# S6E2CC register map
File version: 1.1
CPU: 
Registers are 8-bit, read-write, reset 0x0 unless marked. A register's access mark holds for its fields unless they carry their own. Offsets are from the block's base; [hi:lo] are bit positions; {n}, {i} and the like mark numbered series.

## ETHERNET_MAC0
Base 0x40064000
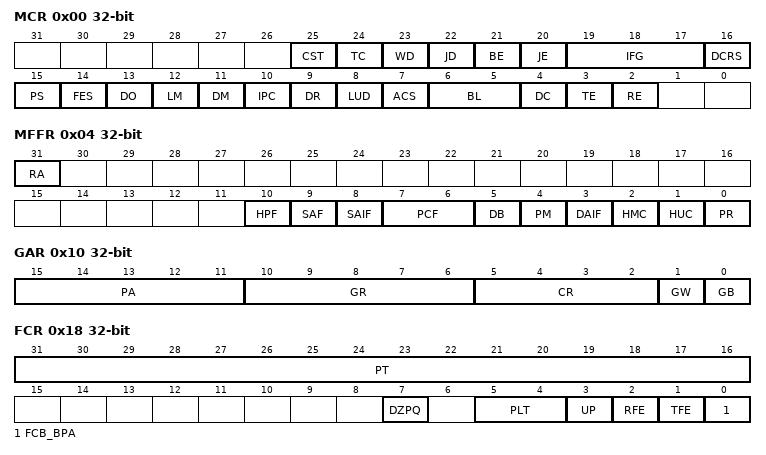
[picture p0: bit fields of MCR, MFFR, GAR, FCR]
0x00 MCR 32-bit — MAC Configuration Register
  [25] CST — CRC stripping for Type frames
  [24] TC — Transmit Configuration in RGMII
  [23] WD — Watchdog Disable
  [22] JD — Jabber Disable
  [21] BE — Frame Burst Enable
  [20] JE — Jumbo Frame Enable
  [19:17] IFG — Inter-Frame GAP
  [16] DCRS — Disable Carrier Sense During Transaction
  [15] PS — Port Select
  [14] FES — Speed
  [13] DO — Disable Receive Own
  [12] LM — Loop-back Mode
  [11] DM — Duplex mode
  [10] IPC — Checksum Offload
  [9] DR — Disable Retry
  [8] LUD — Link Up/Down in RGMII
  [7] ACS — Automatic Pad/CRC Stripping
  [6:5] BL — Back-off Limit
  [4] DC — Deferral Check
  [3] TE — Transmitter Enable
  [2] RE — Receiver Enable
0x04 MFFR 32-bit — MAC Frame Filter Register
  [31] RA — Receive All
  [10] HPF — Hash or Perfect Filter
  [9] SAF — Source Address Filter
  [8] SAIF — Source Address Inverse Filter
  [7:6] PCF — Pass Control Frames
  [5] DB — Disable Broadcast Frames
  [4] PM — Pass All Multicast
  [3] DAIF — DA Inverse Filtering
  [2] HMC — Hash Multicast
  [1] HUC — Hash Unicast
  [0] PR — Promiscuous Mode
0x08 MHTRH 32-bit — MAC Hash Table Register (High)
  [31:0] HTH — the upper 32 bits of the hash table in the HTH
0x0C MHTRL 32-bit — MAC Hash Table Register (Low)
  [31:0] HTL — the lower 32 bits of the hash table in the HTL
0x10 GAR 32-bit — GMII/MII Address Register
  [15:11] PA — Physical Layer Address
  [10:6] GR — GMII Register
  [5:2] CR — Application Clock Range
  [1] GW — GMII/MII Write
  [0] GB — GMII/MII Busy
0x14 GDR 32-bit — GMII/MII Data Register
  [15:0] GD
0x18 FCR 32-bit — Flow Control Register
  [31:16] PT — Pause Time
  [7] DZPQ — Disable Zero-Quanta Pause
  [5:4] PLT — Pause Low Threshold
  [3] UP — Unicast Pause Frame detect
  [2] RFE — Receive Flow Control Enable
  [1] TFE — Transmit Flow Control Enable
  [0] FCB_BPA — Flow Control Busy/Backpressure Activate
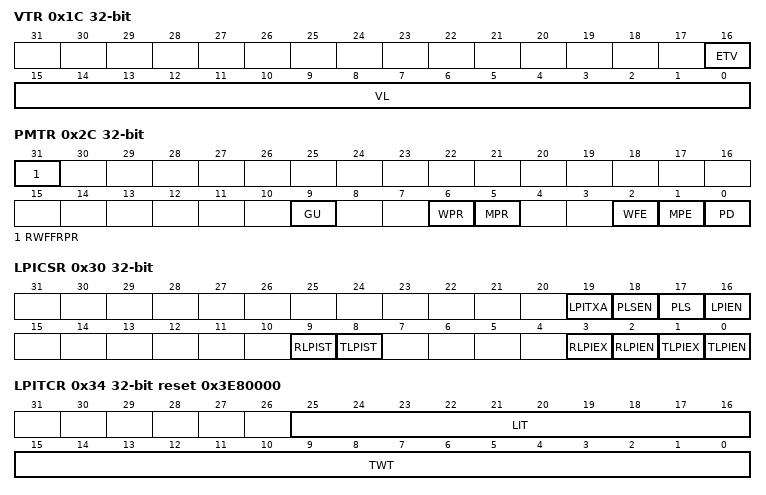
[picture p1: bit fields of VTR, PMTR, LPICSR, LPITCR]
0x1C VTR 32-bit — VLAN TAG Register
  [16] ETV — Enable 12-Bit VLAN Tag Comparison
  [15:0] VL — VLAN Tag Identifier
0x28 RWFFR 32-bit — Remote Wake-up Frame Filter Register
0x2C PMTR 32-bit — PMT Register
  [31] RWFFRPR — Remote Wake-up Frame Filter Register Pointer Reset
  [9] GU — Global Unicast
  [6] WPR — Wake Up Frame Receive
  [5] MPR — Magic Packet Received
  [2] WFE — Wake-Up Frame Enable
  [1] MPE — Magic Packet Enable
  [0] PD — Power Down
0x30 LPICSR 32-bit — LPI Control and Status Register
  [19] LPITXA — LPI TX Automate
  [18] PLSEN — PHY Link Status Enable
  [17] PLS — PHY Link Status
  [16] LPIEN — LPI Enable
  [9] RLPIST ro — Receive LPI State
  [8] TLPIST ro — Transmit LPI State
  [3] RLPIEX ro — Receive LPI Exit
  [2] RLPIEN ro — Receive LPI Entry
  [1] TLPIEX ro — Transmit LPI Exit
  [0] TLPIEN ro — Transmit LPI Entry
0x34 LPITCR 32-bit reset 0x3E80000 — LPI Timers Control Register
  [25:16] LIT — LPI LS TIMER
  [15:0] TWT — LPI TW TIMER
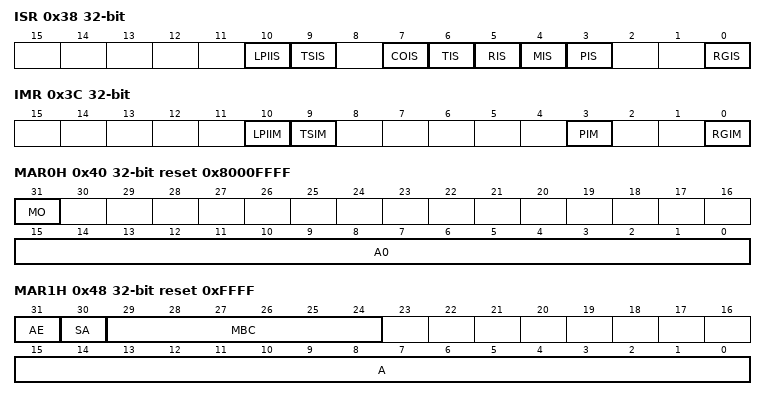
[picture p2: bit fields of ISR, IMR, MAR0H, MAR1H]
0x38 ISR 32-bit ro — Interrupt Status Register
  [10] LPIIS — LPI Interrupt Status
  [9] TSIS — Time Stamp Interrupt Status
  [7] COIS — MMC Receive Checksum Offload Interrupt Status
  [6] TIS — MMC Transmit Interrupt Status
  [5] RIS — MMC Receive Interrupt Status
  [4] MIS — MMC Interrupt Status
  [3] PIS — PMT Interrupt Status
  [0] RGIS — RGMII Interrupt Status
0x3C IMR 32-bit — Interrupt Mask Register
  [10] LPIIM — LPI Interrupt Mask
  [9] TSIM — Time Stamp Interrupt Mask
  [3] PIM — PMT Interrupt Mask
  [0] RGIM — RGMII Interrupt Mask
0x40 MAR0H 32-bit reset 0x8000FFFF — MAC Address0 Register (High)
  [31] MO ro — Must be one
  [15:0] A0 — MAC Address0
0x44 MAR0L 32-bit reset 0xFFFFFFFF — MAC Address0 Register (Low)
  [31:0] A0 — MAC Address0
0x48 MAR1H 32-bit reset 0xFFFF — MAC Address1 Register -High
  [31] AE — Address Enable
  [30] SA — Source Address
  [29:24] MBC — Mask Byte Control
  [15:0] A — MAC Address
0x4C MAR1L 32-bit reset 0xFFFFFFFF — MAC Address1 Register -Low
  [31:0] A — MAC Address
{0x40+8i} MAR{i}H 32-bit reset not defined (i=2..15) — MAC Address{i} Register -High
{0x44+8i} MAR{i}L 32-bit reset not defined (i=2..15) — MAC Address{i} Register -Low
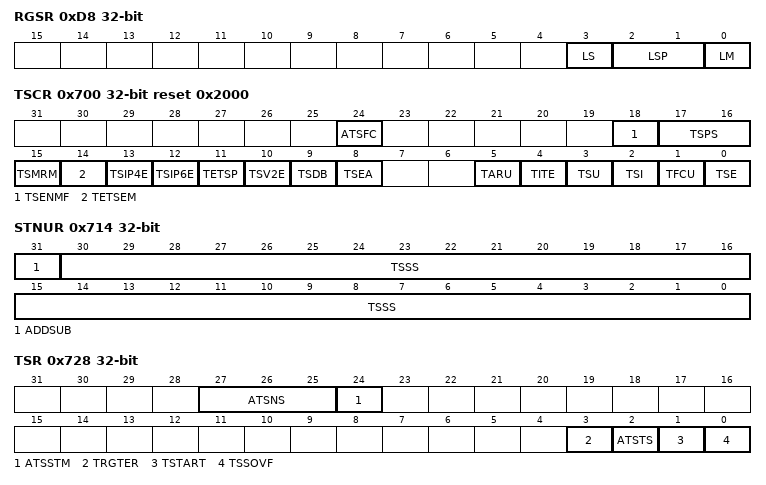
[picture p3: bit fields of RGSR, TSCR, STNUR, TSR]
0xD8 RGSR 32-bit ro — RGMII Status Register)
  [3] LS — Link Status
  [2:1] LSP — Link Speed
  [0] LM — Link Mode
0x100 mmc_cntl 32-bit (reset mask 0x3F) — MMC Control Register
0x104 mmc_intr_rx 32-bit ro (reset mask 0xFFFFFF) — Receive Interrupt Register
0x108 mmc_intr_tx 32-bit ro (reset mask 0x1FFFFFF) — MMC Transmit Interrupt Register
0x10C mmc_intr_mask_rx 32-bit (reset mask 0xFFFFFF) — MMC Receive Interrupt Mask Register
0x110 mmc_intr_mask_tx 32-bit (reset mask 0x1FFFFFF) — MMC Transmit Interrupt Mask Register
0x114 txoctetcount_gb 32-bit ro — "Number of bytes transmitted, exclusive of preamble and retried bytes, in good and bad frames"
0x118 txframecount_gb 32-bit ro — "Number of good and bad frames transmitted, exclusive of retried frames"
0x11C txbroadcastframes_g 32-bit ro — Number of good broadcast frames transmitted
0x120 txmulticastframes_g 32-bit ro — Number of good multicast frames transmitted
0x124 tx64octets_gb 32-bit ro — "Number of good and bad frames transmitted with length of 64 bytes, exclusive of preamble and retried frames"
0x128 tx65to127octets_gb 32-bit ro — "Number of good and bad frames transmitted with length between 65 and 127 (inclusive) bytes, exclusive of preamble and retried frames"
0x12C tx128to255octets_gb 32-bit ro — "Number of good and bad frames transmitted with length between 128 and 255 (inclusive) bytes, exclusive of preamble and retried frames"
0x130 tx256to511octets_gb 32-bit ro — "Number of good and bad frames transmitted with length between 256 and 511 (inclusive) bytes, exclusive of preamble and retried frames"
0x134 tx512to1023octets_gb 32-bit ro — "Number of good and bad frames transmitted with length between 512 and 1023 (inclusive) bytes, exclusive of preamble and retried frames"
0x138 tx1024tomaxoctets_gb 32-bit ro — "Number of good and bad frames transmitted with length between 1024 and Maxsize (inclusive) bytes, exclusive of preamble and retried frames"
0x13C txunicastframes_gb 32-bit ro — Number of good and bad unicast frames transmitted
0x140 txmulticastframes_gb 32-bit ro — Number of good and bad multicast frames transmitted
0x144 txbroadcastframes_gb 32-bit ro — Number of good and bad broadcast frames transmitted
0x148 txunderflowerror 32-bit ro — Number of frames aborted due to frame underflow error
0x14C txsinglecol_g 32-bit ro — Number of successfully transmitted frames after a single collision in Half-duplex mode
0x150 txmulticol_g 32-bit ro — Number of successfully transmitted frames after more than a single collision in Half-duplex mode
0x154 txdeferred 32-bit ro — Number of successfully transmitted frames after a deferral in Half-duplex mode.
0x158 txlatecol 32-bit ro — Number of frames aborted due to late collision error.
0x15C txexesscol 32-bit ro — Number of frames aborted due to excessive (16) collision errors.
0x160 txcarriererror 32-bit ro — Number of frames aborted due to carrier sense error (no carrier or loss of carrier).
0x164 txoctetcount_g 32-bit ro — "Number of bytes transmitted, exclusive of preamble, in good frames only. "
0x168 txframecount_g 32-bit ro — Number of good frames transmitted.
0x16C txexecessdef_g 32-bit ro — Number of frames aborted due to excessive deferral error (deferred for more than two max-sized frame times).
0x170 txpauseframes 32-bit ro — Number of good PAUSE frames transmitted.
0x174 txvlanframes_g 32-bit ro — "Number of good VLAN frames transmitted, exclusive of retried frames. "
0x180 rxframecount_gb 32-bit ro — Number of good and bad frames received.
0x184 rxoctetcount_gb 32-bit ro — "Number of bytes received, exclusive of preamble, in good and bad frames. "
0x188 rxoctetcount_g 32-bit ro — "Number of bytes received, exclusive of preamble, only in good frames. "
0x18C rxbroadcastframes_g 32-bit ro — Number of good broadcast frames received.
0x190 rxmulticastframes_g 32-bit ro — Number of good multicast frames received.
0x194 rxcrcerror 32-bit ro — Number of frames received with CRC error.
0x198 rxallignmenterror 32-bit ro — Number of frames received with alignment (dribble) error. Valid only in 10/100 mode.
0x19C rxrunterror 32-bit ro — Number of frames received with runt (64 bytes and CRC error) error.
0x1A0 rxjabbererror 32-bit ro — Number of frames received with length greater than 1518 bytes with CRC error.
0x1A4 rxundersize_g 32-bit ro — "Number of frames received with length less than 64 bytes, without any errors. "
0x1A8 rxoversize_g 32-bit ro — Number of frames received with length greater than the maxsize without error.
0x1AC rx64octets_gb 32-bit ro — "Number of good and bad frames received with length 64 bytes, exclusive of preamble. "
0x1B0 rx65to127octets_gb 32-bit ro — "Number of good and bad frames received with length between 65 and 127 (inclusive) bytes, exclusive of preamble. "
0x1B4 rx128to255octets_gb 32-bit ro — "Number of good and bad frames received with length between 128 and 255 (inclusive) bytes, exclusive of preamble. "
0x1B8 rx256to511octets_gb 32-bit ro — "Number of good and bad frames received with length between 256 and 511 (inclusive) bytes, exclusive of preamble. "
0x1BC rx512to1023octets_gb 32-bit ro — "Number of good and bad frames received with length between 512 and 1023 (inclusive) bytes, exclusive of preamble. "
0x1C0 rx1024tomaxoctets_gb 32-bit ro — "Number of good and bad frames received with length between 1024 and maxsize (inclusive) bytes, exclusive of preamble. "
0x1C4 rxunicastframes_g 32-bit ro — Number of good unicast frames received.
0x1C8 rxlengtherror 32-bit ro — "Number of frames received with length error (Length type field is not the frame size), for all frames with valid length field. "
0x1CC rxoutofrangetype 32-bit ro — Number of frames received with length/type field not equal to the valid frame size (>1500)
0x1D0 rxpauseframes 32-bit ro — Number of good and valid PAUSE frames received.
0x1D4 rxfifooverflow 32-bit ro — Number of missed received frames due to FIFO overflow.
0x1D8 rxvlanframes_gb 32-bit ro — Number of good and bad VLAN frames received.
0x1DC rxwatchdogerror 32-bit ro — Number of frames received with error due to watchdog timeout error (frames with a data load larger than 2048 bytes).
0x200 mmc_ipc_intr_mask_rx 32-bit (reset mask 0x3FFF3FFF) — MMC Receive Checksum Offload Interrupt Mask Register
0x208 mmc_ipc_intr_rx 32-bit ro (reset mask 0x3FFF3FFF) — MMC Receive Checksum Offload Interrupt Register
0x210 rxipv4_gd_frms 32-bit ro — "Number of good IPv4 datagrams received with the TCP, UDP, or ICMP payload "
0x214 rxipv4_hdrerr_frms 32-bit ro — "Number of IPv4 datagrams received with header errors (checksum, length, or version mismatch) "
0x218 rxipv4_nopay_frms 32-bit ro — "Number of IPv4 datagram frames received that did not have a TCP, UDP, or ICMP payload processed by the Checksum engine "
0x21C rxipv4_frag_frms 32-bit ro — Number of good IPv4 datagrams with fragmentation
0x220 rxipv4_udsbl_frms 32-bit ro — Number of good IPv4 datagrams received that had a UDP payload with checksum disabled
0x224 rxipv6_gd_frms 32-bit ro — "Number of good IPv6 datagrams received with TCP, UDP, or ICMP payloads "
0x228 rxipv6_hdrerr_frms 32-bit ro — Number of IPv6 datagrams received with header errors (length or version mismatch)
0x22C rxipv6_nopay_frms 32-bit ro — "Number of IPv6 datagram frames received that did not have a TCP, UDP, or ICMP payload. This includes all IPv6 datagrams with fragmentation or security extension headers "
0x230 rxudp_gd_frms 32-bit ro — Number of good IP datagrams with a good UDP payload. This counter is not updated when the rxipv4_udsbl_frms counter is incremented.
0x234 rxudp_err_frms 32-bit ro — Number of good IP datagrams whose UDP payload has a checksum error
0x238 rxtcp_gd_frms 32-bit ro — Number of good IP datagrams with a good TCP payload
0x23C rxtcp_err_frms 32-bit ro — Number of good IP datagrams whose TCP payload has a checksum error
0x240 rxicmp_gd_frms 32-bit ro — Number of good IP datagrams with a good ICMP payload
0x244 rxicmp_err_frms 32-bit ro — Number of good IP datagrams whose ICMP payload has a checksum error
0x250 rxipv4_gd_octets 32-bit ro — "Number of bytes received in good IPv4 datagrams encapsulating TCP, UDP, or ICMP data. (Ethernet header, FCS, pad, or IP pad bytes are not included in this counter or in the octet counters listed below). "
0x254 rxipv4_hdrerr_octets 32-bit ro — "Number of bytes received in IPv4 datagrams with header errors (checksum, length, version mismatch). The value in the Length field of IPv4 header is used to update this counter. "
0x258 rxipv4_nopay_octets 32-bit ro — "Number of bytes received in IPv4 datagrams that did not have a TCP, UDP, or ICMP payload. The value in the IPv4 header's Length field is used to update this counter. "
0x25C rxipv4_frag_octets 32-bit ro — Number of bytes received in fragmented IPv4 datagrams. The value in the IPv4 header's Length field is used to update this counter.
0x260 rxipv4_udsbl_octets 32-bit ro — Number of bytes received in a UDP segment that had the UDP checksum disabled. This counter does not count IP Header bytes.
0x264 rxipv6_gd_octets 32-bit ro — "Number of bytes received in good IPv6 datagrams encapsulating TCP, UDP or ICMPv6 data"
0x268 rxipv6_hdrerr_octets 32-bit ro — "Number of bytes received in IPv6 datagrams with header errors (length, version mismatch). The value in the IPv6 header's Length field is used to update this counter. "
0x26C rxipv6_nopay_octets 32-bit ro — "Number of bytes received in IPv6 datagrams that did not have a TCP, UDP, or ICMP payload. The value in the IPv6 header's Length field is used to update this counter. "
0x270 rxudp_gd_octets 32-bit ro — Number of bytes received in a good UDP segment. This counter (and the counters below) does not count IP header bytes.
0x274 rxudp_err_octets 32-bit ro — Number of bytes received in a UDP segment that had checksum errors
0x278 rxtcp_gd_octets 32-bit ro — Number of bytes received in a good TCP segment
0x27C rxtcp_err_octets 32-bit ro — Number of bytes received in a TCP segment with checksum errors
0x280 rxicmp_gd_octets 32-bit ro — Number of bytes received in a good ICMP segment
0x284 rxicmp_err_octets 32-bit ro — Number of bytes received in an ICMP segment with checksum errors
0x700 TSCR 32-bit reset 0x2000 — Time Stamp Control Register
  [24] ATSFC — Auxiliary Snapshot FIFO Clear
  [18] TSENMF — Enable MAC address for PTP frame filtering
  [17:16] TSPS — SelectPTP packets for taking snapshots
  [15] TSMRM — Enable Snapshot for Messages Relevant to Master
  [14] TETSEM — Enable Time Stamp Snapshot for Event Messages
  [13] TSIP4E — Enable Time Stamp Snapshot for IPv4 frames
  [12] TSIP6E — Enable Time Stamp Snapshot for IPv6 frames
  [11] TETSP — Enable Time Stamp Snapshot for PTP over Ethernet frames
  [10] TSV2E — Enable PTP packet snooping for version 2 format
  [9] TSDB — Time Stamp Digital or Binary rollover control
  [8] TSEA — Enable Time Stamp for All Frames
  [5] TARU — Addend Register Update
  [4] TITE — Time Stamp Interrupt Trigger Enable
  [3] TSU — Time Stamp Update
  [2] TSI — Time Stamp Initialize
  [1] TFCU — Time Stamp Fine or Coarse Update
  [0] TSE — Time Stamp Enable
0x704 SSIR 32-bit — Sub-Second Increment Register
  [7:0] SSINC — Sub-Second Increment Value
0x708 STSR 32-bit ro — System Time - Seconds Register
  [31:0] TSS — Time Stamp Second
0x70C STNR 32-bit ro — System Time - Nanoseconds Register
  [30:0] TSSS — Time Stamp Sub-Seconds
0x710 STSUR 32-bit — System Time - Seconds Update Register
  [31:0] TSS — Time Stamp Second
0x714 STNUR 32-bit — System Time - Nanoseconds Update Register
  [31] ADDSUB — Add or Subtract Time
  [30:0] TSSS — Time Stamp Sub-Seconds
0x718 TSAR 32-bit — Time Stamp Addend Register
0x71C TTSR 32-bit — Target Time Seconds Register
  [31:0] TSTR — Target Time Stamp Seconds Register
0x720 TTNR 32-bit — Target Time Nanoseconds Register
  [30:0] TSTR — Target Time Stamp Nanoseconds Register
0x724 STHWSR 32-bit — System Time - Higher Word Seconds Register
  [15:0] TSHWR — Time Stamp Higher Word Register
0x728 TSR 32-bit ro — Time Stamp Status Register
  [27:25] ATSNS — Auxiliary Time Stamp Number of Snapshots
  [24] ATSSTM — Auxiliary Time Stamp Snapshot Trigger Missed
  [3] TRGTER — Timestamp Target Time Error
  [2] ATSTS — Auxiliary Time Stamp Trigger Snapshot
  [1] TSTART — Time Stamp Target Time Reached
  [0] TSSOVF — Time Stamp Seconds Overflow
0x72C PPSCR 32-bit — PPS Control Register
  [3:0] PPSCTRL ro — Controls the frequency of the PPS output
0x730 ATNR 32-bit ro — Auxiliary Time Stamp - Nanoseconds Register
  [30:0] ATN
0x734 ATSR 32-bit ro — Auxiliary Time Stamp - Seconds Register
  [31:0] ATS
{0x780+8i} MAR{i}H 32-bit reset not defined (i=16..31) — MAC Address{i} Register -High
{0x784+8i} MAR{i}L 32-bit reset not defined (i=16..31) — MAC Address{i} Register -Low
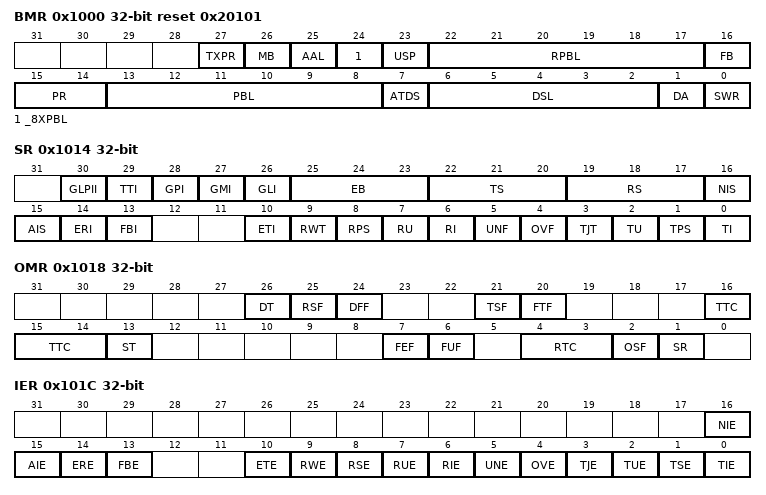
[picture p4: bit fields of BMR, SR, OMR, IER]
0x1000 BMR 32-bit reset 0x20101 — Bus Mode Register
  [27] TXPR — Transmit Priority
  [26] MB — Mixed Burst
  [25] AAL — Address-Aligned Beats
  [24] _8XPBL — 8xPBL Mode
  [23] USP — Use Separate PBL
  [22:17] RPBL — RxDMA PBL
  [16] FB — Fixed Burst
  [15:14] PR — Rx:Tx priority ratio
  [13:8] PBL — Programmable Burst Length
  [7] ATDS — Alternate Descriptor Size
  [6:2] DSL — Descriptor Skip Length
  [1] DA — DMA Arbitration scheme
  [0] SWR — Software Reset
0x1004 TPDR 32-bit — Transmit Poll Demand Register)
  [31:0] TPD — Transmit Poll Demand
0x1008 RPDR 32-bit — Receive Poll Demand Register
  [31:0] RPD — Receive Poll Demand
0x100C RDLAR 32-bit — Receive Descriptor List Address Register)
  [31:2] SRL — Start of Receive List
0x1010 TDLAR 32-bit — Transmit Descriptor List Address Register
  [31:2] STL — Start of Transmit List
0x1014 SR 32-bit ro — Status Register
  [30] GLPII — GMAC LPI Interrupt
  [29] TTI — Time-Stamp Trigger Interrupt
  [28] GPI — GMAC PMT Interrupt
  [27] GMI — GMAC MMC Interrupt
  [26] GLI — GMAC Line interface Interrupt
  [25:23] EB — Error Bits
  [22:20] TS — Transmit Process State
  [19:17] RS — Receive Process State
  [16] NIS — Normal Interrupt Summary
  [15] AIS — Abnormal Interrupt Summary
  [14] ERI — Early Receive Interrupt
  [13] FBI — Fatal Bus Error Interrupt
  [10] ETI — Early Transmit Interrupt
  [9] RWT — Receive Watchdog Timeout
  [8] RPS — Receive process Stopped
  [7] RU — Receive Buffer Unavailable
  [6] RI — Receive Interrupt
  [5] UNF — Transmit underflow
  [4] OVF — Receive Overflow
  [3] TJT — Transmit Jabber Timeout
  [2] TU — Transmit Buffer Unavailable
  [1] TPS — Transmit Process Stopped
  [0] TI — Transmit Interrupt
0x1018 OMR 32-bit — Operation Mode Register
  [26] DT — Disable Dropping of TCP/IP Checksum Error Frames
  [25] RSF — Receive Store and Forward
  [24] DFF — Disable Flushing of Received Frames
  [21] TSF — Transmit Store Forward
  [20] FTF — Flush Transmit FIFO
  [16:14] TTC — Transmit Threshold Control
  [13] ST — Start/Stop Transmission Command
  [7] FEF — Forward Error Frames
  [6] FUF — Forward Undersized Good Frames
  [4:3] RTC — Receive Threshold Control
  [2] OSF — Operate on Second Frame
  [1] SR — Start/Stop Receive
0x101C IER 32-bit — Interrupt Enable Register
  [16] NIE — Normal Interrupt Summary Enable
  [15] AIE — Abnormal Interrupt Summary Enable
  [14] ERE — Early Receive Interrupt Enable
  [13] FBE — Fatal Bus Error Enable
  [10] ETE — Early Transmit Interrupt Enable
  [9] RWE — Receive Watchdog Timeout Enable
  [8] RSE — Receive Process Stopped Enable
  [7] RUE — Receive Buffer Unavailable Enable
  [6] RIE — Receive Interrupt Enable
  [5] UNE — Transmit underflow Enable
  [4] OVE ro — Receive Overflow Enable
  [3] TJE — Transmit Jabber Timeout
  [2] TUE — Transmit Buffer Unavailable
  [1] TSE — Transmit Process Stopped
  [0] TIE — Transmit Interrupt
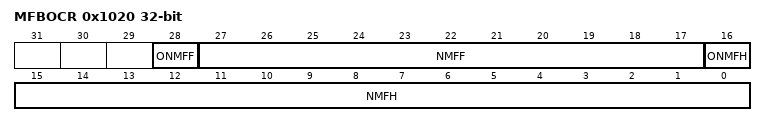
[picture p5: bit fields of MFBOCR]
0x1020 MFBOCR 32-bit ro — Missed Frame and Buffer Overflow Counter Register
  [28] ONMFF — Overflow NMFF
  [27:17] NMFF — Number of Missed frame by Ethernet-MAC
  [16] ONMFH — Overflow NMFH
  [15:0] NMFH — Number of Missed frame by HOST
0x1024 RIWTR 32-bit ro — Receive Interrupt Watchdog Timer Register
  [7:0] RIWT — RI Watchdog Timer count
0x102C AHBSR 32-bit ro — AHB Status Register
  [0] AHBS — AHB Status
0x1048 CHTDR 32-bit ro — Current Host Transmit Descriptor Register
  [31:0] HTDAP — Host Transmit Descriptor Address Pointer
0x104C CHRDR 32-bit ro — Current Host Receive Descriptor Register
  [31:0] HRDAP — Host Receive Descriptor Address Pointer
0x1050 CHTBAR 32-bit ro — Current Host Transmit Buffer Address Register
  [31:0] HTBAR — Host Transmit Buffer Address Register
0x1054 CHRBAR 32-bit ro — Current Host Receive Buffer Address Register
  [31:0] HRBAR — Host Receive Buffer Address Register
